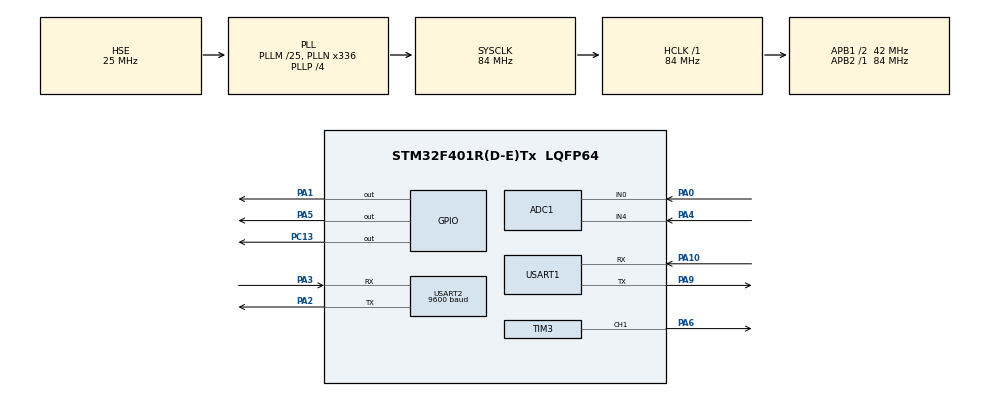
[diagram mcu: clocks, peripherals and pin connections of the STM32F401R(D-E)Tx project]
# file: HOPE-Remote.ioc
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ADC1.Channel-0\#ChannelRegularConversion=ADC_CHANNEL_0
ADC1.ClockPrescaler=ADC_CLOCK_SYNC_PCLK_DIV6
ADC1.NbrOfConversionFlag=1
ADC1.Rank-0\#ChannelRegularConversion=1
ADC1.SamplingTime-0\#ChannelRegularConversion=ADC_SAMPLETIME_3CYCLES
ADC1.master=1
Dma.Request0=TIM3_CH1/TRIG
Dma.TIM3_CH1/TRIG.0.Direction=DMA_MEMORY_TO_PERIPH
Dma.TIM3_CH1/TRIG.0.FIFOMode=DMA_FIFOMODE_DISABLE
Dma.TIM3_CH1/TRIG.0.Instance=DMA1_Stream4
Dma.TIM3_CH1/TRIG.0.MemDataAlignment=DMA_MDATAALIGN_WORD
Dma.TIM3_CH1/TRIG.0.MemInc=DMA_MINC_ENABLE
Dma.TIM3_CH1/TRIG.0.Mode=DMA_NORMAL
Dma.TIM3_CH1/TRIG.0.PeriphDataAlignment=DMA_PDATAALIGN_WORD
Dma.TIM3_CH1/TRIG.0.PeriphInc=DMA_PINC_DISABLE
Dma.TIM3_CH1/TRIG.0.Priority=DMA_PRIORITY_HIGH
Mcu.Family=STM32F4
Mcu.Name=STM32F401R(D-E)Tx
Mcu.Package=LQFP64
NVIC.DMA1_Stream4_IRQn=true\:0\:0\:false\:false\:true\:false\:true\:true
NVIC.PriorityGroup=NVIC_PRIORITYGROUP_4
NVIC.USART1_IRQn=true\:0\:0\:false\:false\:true\:true\:true\:true
NVIC.USART2_IRQn=true\:0\:0\:false\:false\:true\:true\:true\:true
PA0-WKUP.Signal=ADCx_IN0
PA1.GPIO_Speed=GPIO_SPEED_FREQ_HIGH
PA1.Signal=GPIO_Output
PA10.Mode=Asynchronous
PA10.Signal=USART1_RX
PA13.Mode=Serial_Wire
PA13.Signal=SYS_JTMS-SWDIO
PA14.Mode=Serial_Wire
PA14.Signal=SYS_JTCK-SWCLK
PA2.Mode=Asynchronous
PA2.Signal=USART2_TX
PA3.Mode=Asynchronous
PA3.Signal=USART2_RX
PA4.Signal=ADCx_IN4
PA5.GPIO_Speed=GPIO_SPEED_FREQ_HIGH
PA5.Signal=GPIO_Output
PA6.GPIO_Speed=GPIO_SPEED_FREQ_HIGH
PA6.Signal=S_TIM3_CH1
PA9.Mode=Asynchronous
PA9.Signal=USART1_TX
PC13-ANTI_TAMP.PinState=GPIO_PIN_SET
PC13-ANTI_TAMP.Signal=GPIO_Output
PH0\ -\ OSC_IN.Mode=HSE-External-Oscillator
PH0\ -\ OSC_IN.Signal=RCC_OSC_IN
PH1\ -\ OSC_OUT.Mode=HSE-External-Oscillator
PH1\ -\ OSC_OUT.Signal=RCC_OSC_OUT
ProjectManager.HeapSize=0x2000
ProjectManager.StackSize=0x4000
ProjectManager.TargetToolchain=MDK-ARM V5.32
RCC.48MHZClocksFreq_Value=84000000
RCC.AHBFreq_Value=84000000
RCC.APB1CLKDivider=RCC_HCLK_DIV2
RCC.APB1Freq_Value=42000000
RCC.APB1TimFreq_Value=84000000
RCC.APB2Freq_Value=84000000
RCC.APB2TimFreq_Value=84000000
RCC.CortexFreq_Value=84000000
RCC.HCLKFreq_Value=84000000
RCC.HSE_VALUE=25000000
RCC.HSI_VALUE=16000000
RCC.LSE_VALUE=32768
RCC.PLLM=25
RCC.PLLN=336
RCC.PLLP=RCC_PLLP_DIV4
RCC.PLLSourceVirtual=RCC_PLLSOURCE_HSE
RCC.SYSCLKFreq_VALUE=84000000
RCC.SYSCLKSource=RCC_SYSCLKSOURCE_PLLCLK
RCC.VCOOutputFreq_Value=336000000
SH.ADCx_IN0.0=ADC1_IN0,IN0
SH.ADCx_IN4.0=ADC1_IN4,IN4
SH.S_TIM3_CH1.0=TIM3_CH1,PWM Generation1 CH1
TIM2.Period=0xFFFFFFFF
TIM2.Prescaler=84 - 1
TIM3.Channel-PWM\ Generation1\ CH1=TIM_CHANNEL_1
TIM3.Period=105 - 1
TIM3.Prescaler=1 - 1
USART1.VirtualMode=VM_ASYNC
USART2.BaudRate=9600
USART2.VirtualMode=VM_ASYNC
VP_TIM2_VS_ClockSourceINT.Mode=Internal
VP_TIM3_VS_ClockSourceINT.Mode=Internal
board=custom

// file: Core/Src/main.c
/* USER CODE BEGIN Header */
/**
  ******************************************************************************
  * @file           : main.c
  * @brief          : Main program body
  ******************************************************************************
  * @attention
  *
  * Copyright (c) 2026 STMicroelectronics.
  * All rights reserved.
  *
  * This software is licensed under terms that can be found in the LICENSE file
  * in the root directory of this software component.
  * If no LICENSE file comes with this software, it is provided AS-IS.
  *
  ******************************************************************************
  */
/* USER CODE END Header */
#include "main.h"
#include "adc.h"
#include "dma.h"
#include "tim.h"
#include "usart.h"
#include "gpio.h"

/* USER CODE BEGIN Includes */
#include "common_inc.h"
/* USER CODE END Includes */

void SystemClock_Config(void);

int main(void)
{

  /* MCU Configuration--------------------------------------------------------*/

  /* Reset of all peripherals, Initializes the Flash interface and the Systick. */
  HAL_Init();

  /* Configure the system clock */
  SystemClock_Config();

  /* Initialize all configured peripherals */
  MX_GPIO_Init();
  MX_DMA_Init();
  MX_USART1_UART_Init();
  MX_ADC1_Init();
  MX_TIM2_Init();
  MX_TIM3_Init();
  MX_USART2_UART_Init();
  /* USER CODE BEGIN 2 */

  // Invoke cpp-version main().
  Main();

  /* USER CODE END 2 */

  /* Infinite loop */
  while (1)
  {

  }
}

void SystemClock_Config(void)
{
  RCC_OscInitTypeDef RCC_OscInitStruct = {0};
  RCC_ClkInitTypeDef RCC_ClkInitStruct = {0};

  /** Configure the main internal regulator output voltage
  */
  __HAL_RCC_PWR_CLK_ENABLE();
  __HAL_PWR_VOLTAGESCALING_CONFIG(PWR_REGULATOR_VOLTAGE_SCALE2);

  /** Initializes the RCC Oscillators according to the specified parameters
  * in the RCC_OscInitTypeDef structure.
  */
  RCC_OscInitStruct.OscillatorType = RCC_OSCILLATORTYPE_HSE;
  RCC_OscInitStruct.HSEState = RCC_HSE_ON;
  RCC_OscInitStruct.PLL.PLLState = RCC_PLL_ON;
  RCC_OscInitStruct.PLL.PLLSource = RCC_PLLSOURCE_HSE;
  RCC_OscInitStruct.PLL.PLLM = 25;
  RCC_OscInitStruct.PLL.PLLN = 336;
  RCC_OscInitStruct.PLL.PLLP = RCC_PLLP_DIV4;
  RCC_OscInitStruct.PLL.PLLQ = 4;
  if (HAL_RCC_OscConfig(&RCC_OscInitStruct) != HAL_OK)
  {
    Error_Handler();
  }

  /** Initializes the CPU, AHB and APB buses clocks
  */
  RCC_ClkInitStruct.ClockType = RCC_CLOCKTYPE_HCLK|RCC_CLOCKTYPE_SYSCLK
                              |RCC_CLOCKTYPE_PCLK1|RCC_CLOCKTYPE_PCLK2;
  RCC_ClkInitStruct.SYSCLKSource = RCC_SYSCLKSOURCE_PLLCLK;
  RCC_ClkInitStruct.AHBCLKDivider = RCC_SYSCLK_DIV1;
  RCC_ClkInitStruct.APB1CLKDivider = RCC_HCLK_DIV2;
  RCC_ClkInitStruct.APB2CLKDivider = RCC_HCLK_DIV1;

  if (HAL_RCC_ClockConfig(&RCC_ClkInitStruct, FLASH_LATENCY_2) != HAL_OK)
  {
    Error_Handler();
  }
}

void Error_Handler(void)
{
  __disable_irq();
  while (1)
  {
  }
}
